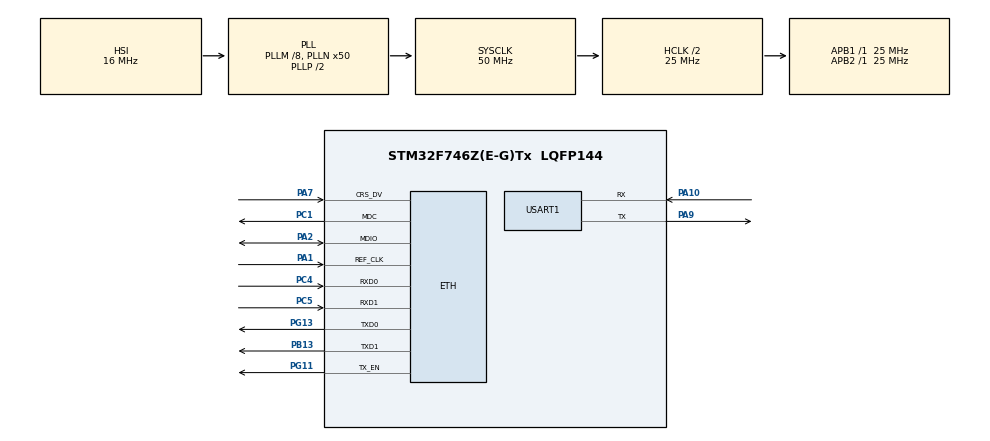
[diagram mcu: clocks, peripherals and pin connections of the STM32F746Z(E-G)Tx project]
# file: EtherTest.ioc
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ETH.AutoNegotiation=ETH_AUTONEGOTIATION_ENABLE
ETH.MediaInterface=ETH_MEDIA_INTERFACE_RMII
ETH.PhyAddress=0
FREERTOS.Tasks01=defaultTask,0,128,StartDefaultTask,Default,NULL
LWIP.GATEWAY_ADDRESS=010.002.006.001
LWIP.IP_ADDRESS=010.002.006.252
LWIP.LWIP_DHCP=0
LWIP.LWIP_FIONREAD_LINUXMODE=0
LWIP.LWIP_NETCONN=1
LWIP.LWIP_NETCONN_FULLDUPLEX=0
LWIP.LWIP_NETCONN_SEM_PER_THREAD=0
LWIP.LWIP_POSIX_SOCKETS_IO_NAMES=0
LWIP.LWIP_SOCKET_SET_ERRNO=0
LWIP.LWIP_SO_LINGER=0
LWIP.LWIP_SO_RCVBUF=0
LWIP.LWIP_SO_RCVTIMEO=0
LWIP.LWIP_SO_SNDRCVTIMEO_NONSTANDARD=0
LWIP.LWIP_SO_SNDTIMEO=0
LWIP.LWIP_TCPIP_TIMEOUT=0
LWIP.LWIP_TCP_KEEPALIVE=0
LWIP.NETMASK_ADDRESS=255.255.255.000
LWIP.SO_REUSE=0
LWIP.SO_REUSE_RXTOALL=0
LWIP.Version=v2.0.0_Cube
Mcu.Family=STM32F7
Mcu.Name=STM32F746Z(E-G)Tx
Mcu.Package=LQFP144
NVIC.ETH_IRQn=true\:5\:0\:false\:false\:true\:true
NVIC.PriorityGroup=NVIC_PRIORITYGROUP_4
NVIC.TIM1_UP_TIM10_IRQn=true\:0\:0\:false\:false\:true\:false
NVIC.TimeBase=TIM1_UP_TIM10_IRQn
NVIC.TimeBaseIP=TIM1
PA1.Mode=RMII
PA1.Signal=ETH_REF_CLK
PA10.Mode=Asynchronous
PA10.Signal=USART1_RX
PA13.Mode=Serial_Wire
PA13.Signal=SYS_JTMS-SWDIO
PA14.Mode=Serial_Wire
PA14.Signal=SYS_JTCK-SWCLK
PA2.Mode=RMII
PA2.Signal=ETH_MDIO
PA7.Mode=RMII
PA7.Signal=ETH_CRS_DV
PA9.Mode=Asynchronous
PA9.Signal=USART1_TX
PB13.Mode=RMII
PB13.Signal=ETH_TXD1
PC1.Mode=RMII
PC1.Signal=ETH_MDC
PC4.Mode=RMII
PC4.Signal=ETH_RXD0
PC5.Mode=RMII
PC5.Signal=ETH_RXD1
PG11.Mode=RMII
PG11.Signal=ETH_TX_EN
PG13.Mode=RMII
PG13.Signal=ETH_TXD0
ProjectManager.HeapSize=0x200
ProjectManager.StackSize=0x400
ProjectManager.TargetToolchain=EWARM
RCC.AHBCLKDivider=RCC_SYSCLK_DIV2
RCC.AHBFreq_Value=25000000
RCC.APB1Freq_Value=25000000
RCC.APB1TimFreq_Value=25000000
RCC.APB2Freq_Value=25000000
RCC.APB2TimFreq_Value=25000000
RCC.CortexFreq_Value=25000000
RCC.HCLKFreq_Value=25000000
RCC.HSE_VALUE=25000000
RCC.HSI_VALUE=16000000
RCC.LSE_VALUE=32768
RCC.PLLM=8
RCC.PLLN=50
RCC.PLLP=RCC_PLLP_DIV2
RCC.SYSCLKFreq_VALUE=50000000
RCC.SYSCLKSource=RCC_SYSCLKSOURCE_PLLCLK
RCC.USBFreq_Value=50000000
RCC.VCOOutputFreq_Value=100000000
USART1.VirtualMode-Asynchronous=VM_ASYNC
USART1.WordLength=WORDLENGTH_8B
VP_FREERTOS_VS_ENABLE.Mode=Enabled
VP_LWIP_VS_Enabled.Mode=Enabled
VP_SYS_VS_tim1.Mode=TIM1
board=EtherTest

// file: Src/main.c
/**
  ******************************************************************************
  * File Name          : main.c
  * Description        : Main program body
  ******************************************************************************
  *
  * Copyright (c) 2017 STMicroelectronics International N.V.
  * All rights reserved.
  *
  * Redistribution and use in source and binary forms, with or without
  * modification, are permitted, provided that the following conditions are met:
  *
  * 1. Redistribution of source code must retain the above copyright notice,
  *    this list of conditions and the following disclaimer.
  * 2. Redistributions in binary form must reproduce the above copyright notice,
  *    this list of conditions and the following disclaimer in the documentation
  *    and/or other materials provided with the distribution.
  * 3. Neither the name of STMicroelectronics nor the names of other
  *    contributors to this software may be used to endorse or promote products
  *    derived from this software without specific written permission.
  * 4. This software, including modifications and/or derivative works of this
  *    software, must execute solely and exclusively on microcontroller or
  *    microprocessor devices manufactured by or for STMicroelectronics.
  * 5. Redistribution and use of this software other than as permitted under
  *    this license is void and will automatically terminate your rights under
  *    this license.
  *
  * THIS SOFTWARE IS PROVIDED BY STMICROELECTRONICS AND CONTRIBUTORS "AS IS"
  * AND ANY EXPRESS, IMPLIED OR STATUTORY WARRANTIES, INCLUDING, BUT NOT
  * LIMITED TO, THE IMPLIED WARRANTIES OF MERCHANTABILITY, FITNESS FOR A
  * PARTICULAR PURPOSE AND NON-INFRINGEMENT OF THIRD PARTY INTELLECTUAL PROPERTY
  * RIGHTS ARE DISCLAIMED TO THE FULLEST EXTENT PERMITTED BY LAW. IN NO EVENT
  * SHALL STMICROELECTRONICS OR CONTRIBUTORS BE LIABLE FOR ANY DIRECT, INDIRECT,
  * INCIDENTAL, SPECIAL, EXEMPLARY, OR CONSEQUENTIAL DAMAGES (INCLUDING, BUT NOT
  * LIMITED TO, PROCUREMENT OF SUBSTITUTE GOODS OR SERVICES; LOSS OF USE, DATA,
  * OR PROFITS; OR BUSINESS INTERRUPTION) HOWEVER CAUSED AND ON ANY THEORY OF
  * LIABILITY, WHETHER IN CONTRACT, STRICT LIABILITY, OR TORT (INCLUDING
  * NEGLIGENCE OR OTHERWISE) ARISING IN ANY WAY OUT OF THE USE OF THIS SOFTWARE,
  * EVEN IF ADVISED OF THE POSSIBILITY OF SUCH DAMAGE.
  *
  ******************************************************************************
  */
#include "main.h"
#include "stm32f7xx_hal.h"
#include "cmsis_os.h"
#include "lwip.h"

/* USER CODE BEGIN Includes */
#include "UART.h"
/* USER CODE END Includes */

UART_HandleTypeDef huart1;

osThreadId defaultTaskHandle;

/* USER CODE BEGIN PV */
/* Private variables ---------------------------------------------------------*/

/* USER CODE END PV */

void SystemClock_Config(void);
void Error_Handler(void);
static void MX_GPIO_Init(void);
static void MX_USART1_UART_Init(void);
void StartDefaultTask(void const * argument);

/* USER CODE BEGIN PFP */
/* Private function prototypes -----------------------------------------------*/

/* USER CODE END PFP */

int main(void)
{

  /* MCU Configuration----------------------------------------------------------*/

  /* Reset of all peripherals, Initializes the Flash interface and the Systick. */
  HAL_Init();

  /* Configure the system clock */
  SystemClock_Config();

  /* Initialize all configured peripherals */
  MX_GPIO_Init();
  MX_USART1_UART_Init();

  /* USER CODE BEGIN 2 */
  APP_DEBUG("\r\n--- Main: Hello world\r\n");
  /* USER CODE END 2 */

  /* Create the thread(s) */
  /* definition and creation of defaultTask */
  osThreadDef(defaultTask, StartDefaultTask, osPriorityNormal, 0, 128);
  defaultTaskHandle = osThreadCreate(osThread(defaultTask), NULL);

  /* Start scheduler */
  osKernelStart();

  /* We should never get here as control is now taken by the scheduler */

  /* Infinite loop */
  while (1)
  {

  }

}

/** System Clock Configuration
*/
void SystemClock_Config(void)
{

  RCC_OscInitTypeDef RCC_OscInitStruct;
  RCC_ClkInitTypeDef RCC_ClkInitStruct;
  RCC_PeriphCLKInitTypeDef PeriphClkInitStruct;

    /**Configure the main internal regulator output voltage
    */
  __HAL_RCC_PWR_CLK_ENABLE();

  __HAL_PWR_VOLTAGESCALING_CONFIG(PWR_REGULATOR_VOLTAGE_SCALE3);

    /**Initializes the CPU, AHB and APB busses clocks
    */
  RCC_OscInitStruct.OscillatorType = RCC_OSCILLATORTYPE_HSI;
  RCC_OscInitStruct.HSIState = RCC_HSI_ON;
  RCC_OscInitStruct.HSICalibrationValue = 16;
  RCC_OscInitStruct.PLL.PLLState = RCC_PLL_ON;
  RCC_OscInitStruct.PLL.PLLSource = RCC_PLLSOURCE_HSI;
  RCC_OscInitStruct.PLL.PLLM = 8;
  RCC_OscInitStruct.PLL.PLLN = 50;
  RCC_OscInitStruct.PLL.PLLP = RCC_PLLP_DIV2;
  RCC_OscInitStruct.PLL.PLLQ = 2;
  if (HAL_RCC_OscConfig(&RCC_OscInitStruct) != HAL_OK)
  {
    Error_Handler();
  }

    /**Initializes the CPU, AHB and APB busses clocks
    */
  RCC_ClkInitStruct.ClockType = RCC_CLOCKTYPE_HCLK|RCC_CLOCKTYPE_SYSCLK
                              |RCC_CLOCKTYPE_PCLK1|RCC_CLOCKTYPE_PCLK2;
  RCC_ClkInitStruct.SYSCLKSource = RCC_SYSCLKSOURCE_PLLCLK;
  RCC_ClkInitStruct.AHBCLKDivider = RCC_SYSCLK_DIV2;
  RCC_ClkInitStruct.APB1CLKDivider = RCC_HCLK_DIV1;
  RCC_ClkInitStruct.APB2CLKDivider = RCC_HCLK_DIV1;

  if (HAL_RCC_ClockConfig(&RCC_ClkInitStruct, FLASH_LATENCY_0) != HAL_OK)
  {
    Error_Handler();
  }

  PeriphClkInitStruct.PeriphClockSelection = RCC_PERIPHCLK_USART1;
  PeriphClkInitStruct.Usart1ClockSelection = RCC_USART1CLKSOURCE_PCLK2;
  if (HAL_RCCEx_PeriphCLKConfig(&PeriphClkInitStruct) != HAL_OK)
  {
    Error_Handler();
  }

    /**Configure the Systick interrupt time
    */
  HAL_SYSTICK_Config(HAL_RCC_GetHCLKFreq()/1000);

    /**Configure the Systick
    */
  HAL_SYSTICK_CLKSourceConfig(SYSTICK_CLKSOURCE_HCLK);

  /* SysTick_IRQn interrupt configuration */
  HAL_NVIC_SetPriority(SysTick_IRQn, 15, 0);
}

/* USART1 init function */
static void MX_USART1_UART_Init(void)
{

  huart1.Instance = USART1;
  huart1.Init.BaudRate = 115200;
  huart1.Init.WordLength = UART_WORDLENGTH_8B;
  huart1.Init.StopBits = UART_STOPBITS_1;
  huart1.Init.Parity = UART_PARITY_NONE;
  huart1.Init.Mode = UART_MODE_TX_RX;
  huart1.Init.HwFlowCtl = UART_HWCONTROL_NONE;
  huart1.Init.OverSampling = UART_OVERSAMPLING_16;
  huart1.Init.OneBitSampling = UART_ONE_BIT_SAMPLE_DISABLE;
  huart1.AdvancedInit.AdvFeatureInit = UART_ADVFEATURE_NO_INIT;
  if (HAL_UART_Init(&huart1) != HAL_OK)
  {
    Error_Handler();
  }

}

/** Configure pins as
        * Analog
        * Input
        * Output
        * EVENT_OUT
        * EXTI
*/
static void MX_GPIO_Init(void)
{

  /* GPIO Ports Clock Enable */
  __HAL_RCC_GPIOC_CLK_ENABLE();
  __HAL_RCC_GPIOA_CLK_ENABLE();
  __HAL_RCC_GPIOB_CLK_ENABLE();
  __HAL_RCC_GPIOG_CLK_ENABLE();

}

/* StartDefaultTask function */
void StartDefaultTask(void const * argument)
{
  /* init code for LWIP */
  MX_LWIP_Init();

  for(;;)
  {
    osDelay(1);
  }
}

void HAL_TIM_PeriodElapsedCallback(TIM_HandleTypeDef *htim)
{
  if (htim->Instance == TIM1) {
    HAL_IncTick();
  }
}

void Error_Handler(void)
{
  while(1)
  {
  }
}

/************************ (C) COPYRIGHT STMicroelectronics *****END OF FILE****/
